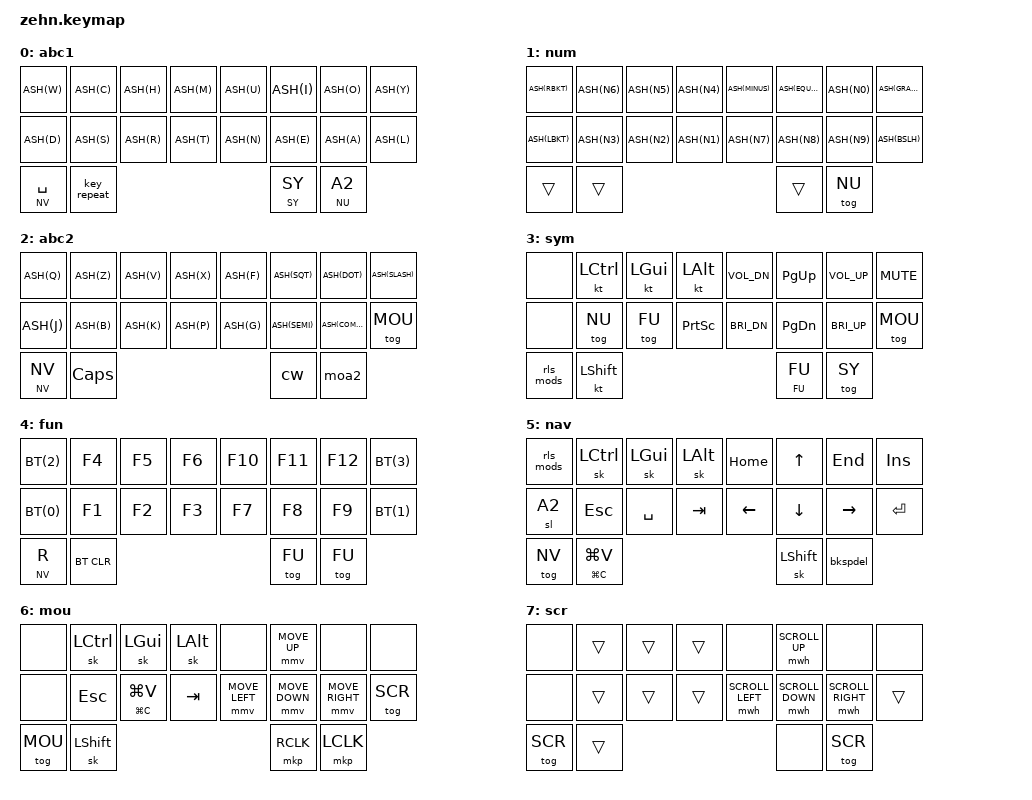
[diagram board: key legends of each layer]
#include <behaviors.dtsi>
#include <dt-bindings/zmk/keys.h>
#include <dt-bindings/zmk/bt.h>
#include <dt-bindings/zmk/mouse.h>

&caps_word { continue-list = <MINUS UNDERSCORE BKSP DEL LEFT RIGHT DOT COMMA SEMI SLASH>; };
&sk { release-after-ms = <3000>; quick-release; ignore-modifiers; };
&sl { release-after-ms = <1000>; };
&lt { tapping-term-ms = <200>; };

#define A1 0
#define NU 1
#define A2 2
#define SY 3
#define FU 4
#define NV 5
#define MOU 6
#define SCR 7

#define ASH(l) &tkp LS(l) l
#define BT(d) &bt BT_SEL d
#define COPYPASTE &tkp LG(C) LG(V)

#define U_MOUSE_MOVE_MAX 1200 /* max speed. default is 600 */
#undef MOVE_UP
#undef MOVE_DOWN
#undef MOVE_LEFT
#undef MOVE_RIGHT
#define MOVE_UP MOVE_VERT(-U_MOUSE_MOVE_MAX)
#define MOVE_DOWN MOVE_VERT(U_MOUSE_MOVE_MAX)
#define MOVE_LEFT MOVE_HOR(-U_MOUSE_MOVE_MAX)
#define MOVE_RIGHT MOVE_HOR(U_MOUSE_MOVE_MAX)

#define U_MOUSE_SCROLL_MAX 20 /* <--- New max speed setting (default: 10) */
#undef SCROLL_UP
#undef SCROLL_DOWN
#undef SCROLL_LEFT
#undef SCROLL_RIGHT
#define SCROLL_UP SCROLL_VERT(-U_MOUSE_SCROLL_MAX)
#define SCROLL_DOWN SCROLL_VERT(U_MOUSE_SCROLL_MAX)
#define SCROLL_LEFT SCROLL_HOR(U_MOUSE_SCROLL_MAX)
#define SCROLL_RIGHT SCROLL_HOR(-U_MOUSE_SCROLL_MAX)

&mmv { acceleration-exponent=<2>; time-to-max-speed-ms = <1500>;};
&mwh { acceleration-exponent=<1>; time-to-max-speed-ms = <1500>;};

/ {
    macros {
        rls_mods: rls_mods { compatible = "zmk,behavior-macro"; label = "ZM_rls_mods"; #binding-cells = <0>; wait-ms = <5>; tap-ms = <15>;
            bindings = <&macro_release &kp LSHFT &kp LCTRL &kp LALT &kp LGUI>; };
        cw:       cw_on_sl { compatible = "zmk,behavior-macro"; label = "ZM_cw_on_sl"; #binding-cells = <0>; wait-ms = <35>; tap-ms = <35>;
            bindings = <&macro_tap &caps_word &kp LSHFT>; }; 
        moa2:     mom_a2   { compatible = "zmk,behavior-macro"; label = "ZM_mom_a2";   #binding-cells = <0>; wait-ms = <35>; tap-ms = <35>;
            bindings = <&macro_tap &kp LSHFT>, <&macro_press &mo A2>, <&macro_pause_for_release>, <&macro_release &mo A2>; }; 
    };

    behaviors {
        mosl: moml_1shot_l { compatible = "zmk,behavior-hold-tap"; label = "MOML_1SHOT_L"; #binding-cells = <2>; flavor = "tap-preferred"; tapping-term-ms = <200>; bindings = <&mo>, <&sl>; }; 
        tosl: togl_1shot_l { compatible = "zmk,behavior-hold-tap"; label = "TOGL_1SHOT_L"; #binding-cells = <2>; flavor = "tap-preferred"; tapping-term-ms = <200>; bindings = <&tog>, <&sl>; }; 
        mokp: moml_kp      { compatible = "zmk,behavior-hold-tap"; label = "MOML_KP";      #binding-cells = <2>; flavor = "tap-preferred"; tapping-term-ms = <200>; bindings = <&mo>, <&kp>; }; 
        moto: mom_tog_l    { compatible = "zmk,behavior-hold-tap"; label = "MOM_TOG_L";    #binding-cells = <2>; flavor = "tap-preferred"; tapping-term-ms = <200>; bindings = <&mo>, <&tog>; }; 
        mokr: mom_key_rep  { compatible = "zmk,behavior-hold-tap"; label = "MOM_KEY_REP";  #binding-cells = <2>; flavor = "tap-preferred"; tapping-term-ms = <200>; bindings = <&mo>, <&key_repeat>; }; 
        tkp:  two_kp       { compatible = "zmk,behavior-hold-tap"; label = "TWO_KP";       #binding-cells = <2>; flavor = "tap-preferred"; tapping-term-ms = <200>; bindings = <&kp>, <&kp>; }; 

        bkspdel: back_del  { compatible = "zmk,behavior-mod-morph"; label = "BACK_DEL";   #binding-cells = <0>; bindings = <&kp BKSP>, <&kp DEL>; mods = <(MOD_LSFT)>; }; 
    };

    keymap {
        compatible = "zmk,keymap";
        abc1 { 
        bindings = <
                ASH(W)  ASH(C)  ASH(H)  ASH(M)     ASH(U)  ASH(I)  ASH(O)  ASH(Y) 
                ASH(D)  ASH(S)  ASH(R)  ASH(T)     ASH(N)  ASH(E)  ASH(A)  ASH(L) 
                   &mokp NV SPACE  &key_repeat     &mosl SY SY  &mosl NU A2 
            >;
        };

        num {
            bindings = <
                ASH(RBKT)  ASH(N6)  ASH(N5)  ASH(N4)     ASH(MINUS)  ASH(EQUAL)  ASH(N0)  ASH(GRAVE) 
                ASH(LBKT)  ASH(N3)  ASH(N2)  ASH(N1)     ASH(N7)     ASH(N8)     ASH(N9)  ASH(BSLH) 
                                      &trans  &trans     &trans  &tog NU 
            >;
         };

        abc2 {
             bindings = <
                ASH(Q)  ASH(Z)  ASH(V)  ASH(X)     ASH(F)  ASH(SQT)   ASH(DOT)    ASH(SLASH) 
                ASH(J)  ASH(B)  ASH(K)  ASH(P)     ASH(G)  ASH(SEMI)  ASH(COMMA)  &tog MOU 
                         &moto NV NV  &kp CAPS     &cw  &moa2
            >;
        };

        sym {
            bindings = <
                &none  &kt LCTRL  &kt LGUI  &kt LALT      &kp C_VOL_DN  &kp PG_UP  &kp C_VOL_UP  &kp C_MUTE 
                &none  &tog NU    &tog FU   &kp PSCRN     &kp C_BRI_DN  &kp PG_DN  &kp C_BRI_UP  &tog MOU 
                                 &rls_mods  &kt LSHFT     &mosl FU FU  &tog SY
            >;
        };

        fun {
            bindings = <
                BT(2)  &kp F4  &kp F5  &kp F6     &kp F10  &kp F11  &kp F12  BT(3) 
                BT(0)  &kp F1  &kp F2  &kp F3     &kp F7   &kp F8   &kp F9   BT(1) 
                       &mokr NV R  &bt BT_CLR     &tog FU  &tog FU 
            >;
        };

        nav {
            bindings = <
                &rls_mods  &sk LCTRL  &sk LGUI   &sk LALT     &kp HOME   &kp UP    &kp END    &kp INS 
                &sl A2     &kp ESC    &kp SPACE  &kp TAB      &kp LEFT   &kp DOWN  &kp RIGHT  &kp ENTER 
                                        &tog NV  COPYPASTE    &sk LSHFT  &bkspdel 
            >;
        };

        mou {
            bindings = <
                &none  &sk LCTRL  &sk LGUI   &sk LALT     &none           &mmv MOVE_UP    &none            &none 
                &none  &kp ESC    COPYPASTE  &kp TAB      &mmv MOVE_LEFT  &mmv MOVE_DOWN  &mmv MOVE_RIGHT  &tog SCR 
                                  &tog MOU  &sk LSHFT     &mkp RCLK  &mkp LCLK 
            >;
        };

        scr {
            bindings = <
                &none  &trans  &trans  &trans     &none             &mwh SCROLL_UP    &none              &none 
                &none  &trans  &trans  &trans     &mwh SCROLL_LEFT  &mwh SCROLL_DOWN  &mwh SCROLL_RIGHT  &trans 
                             &tog SCR  &trans     &none  &tog SCR 
            >;
        };
    };
};
